# PIC32CX0525SG12144 register map
Vendor: Microchip Technology; Series: 0525SG12; File version: 0
CPU: CM4 r1p0, little endian, no MPU, no FPU, 3 interrupt priority bits, 172 interrupts
Registers are 32-bit, read-write, reset 0x0 unless marked. A register's access mark holds for its fields unless they carry their own. Offsets are from the block's base; [hi:lo] are bit positions; {n}, {i} and the like mark numbered series; 'fields as' and 'values as' point back to an identical list.

## DMA_MAIN — DMA Main Registers
Base 0x40002400
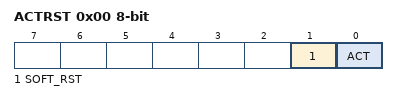
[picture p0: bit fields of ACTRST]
0x00 ACTRST 8-bit — Soft reset the entire module. Enable the blocks operation.
  [1] SOFT_RST — Soft reset the entire module. This bit is self-clearing.
  [0] ACT — Enable the blocks operation. (R/WS). 1=Enable block. Each individual channel must be enabled separately. 0=Disable all channels.
0x04 DATA_PKT ro — Debug register that has the data that is stored in the Data Packet. This data is read data from the currently active transfer source.

## ESPI_MSVW00_06 — The ESPI VW Channel permits the System to emulate a set of wires that interconnect the system Core Logic with the EC
Base 0x400F9C00
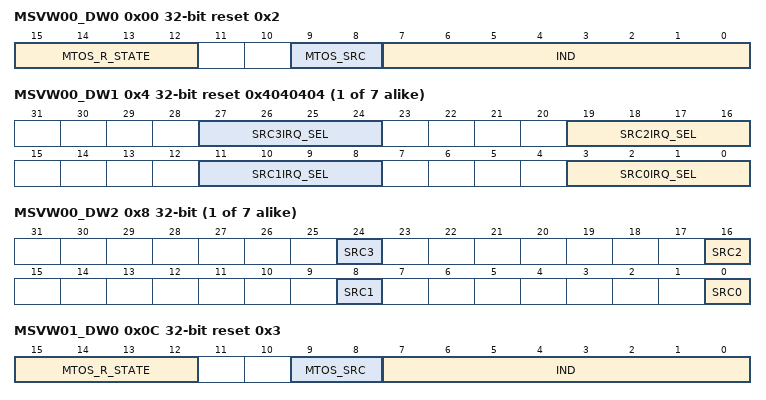
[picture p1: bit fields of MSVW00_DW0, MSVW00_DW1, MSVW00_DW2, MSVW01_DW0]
0x00 MSVW00_DW0 reset 0x2 — Master-to-Slave Virtual Wire 0 Register (DW 0)
  [15:12] MTOS_R_STATE — The four bits in this field are loaded into SRC0, SRC1, SRC2 and SRC3 when the reset signal selected by M2S RESET SRC is asserted. If MTOS_SRC is set for RESET_SYS, the SRC bits are set to the default value of this field, rather than its programmed value, since this field is also reset on RESET_SYS.
  [9:8] MTOS_SRC — This field determines which reset signal in addition to RESET_SYS resets SRC[3:0] in this register: 3=PLTRST. 2=RESET_SIO. 1=RESET_SYS. This is the only reset signal that will reset the SRC fields. 0=RESET_ESPI.
  [7:0] IND — The Index for SRC0, SRC1, SRC2 and SRC3. When the Index field of an incoming Master-to-Slave Virtual Wire transaction matches this value, the fields SRC0, SRC1, SRC2 and SRC3 are updated by the data contained in the respective bit positions in the transaction. Setting the INDEX field to 0 disables the register from accepting any Virtual Wire traffic from the Master. Setting the. INDEX field to 1 is illegal, since INDEX=1 is reserved for Serial IRQ.
{0x4+0xC*i} MSVW{i:02}_DW1 reset 0x4040404 (i=0..6) — Master-to-Slave Virtual Wire {i} Register (DW 1)
  [8n+3:8n] SRC{n}IRQ_SEL (n=0..3) — A change in the value of SRC{n} will generate an interrupt to the EC. Changes in the SRC register value caused by a Reset Event do not generate an interrupt.
{0x8+0xC*i} MSVW{i:02}_DW2 (i=0..6) — Master-to-Slave Virtual Wire {i} Register (DW 2)
  [8n] SRC{n} (n=0..3) — Master-to-Slave data for Bit Position {n} for the virtual wire associated with the index defined by INDEX.
0x0C MSVW01_DW0 reset 0x3 — Master-to-Slave Virtual Wire 1 Register (DW 0)
  fields as MSVW00_DW0
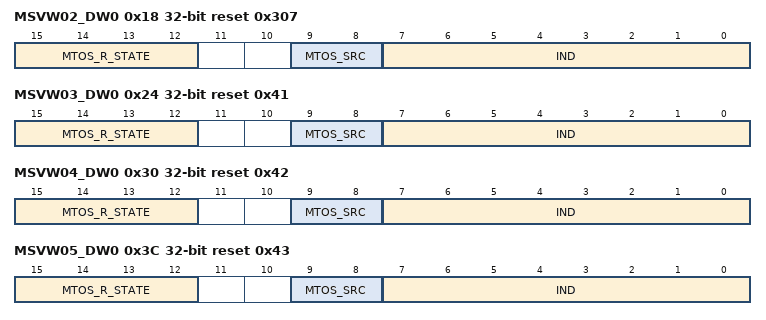
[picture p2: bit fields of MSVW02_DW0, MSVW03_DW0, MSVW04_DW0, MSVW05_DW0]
0x18 MSVW02_DW0 reset 0x307 — Master-to-Slave Virtual Wire 2 Register (DW 0)
  fields as MSVW00_DW0
0x24 MSVW03_DW0 reset 0x41 — Master-to-Slave Virtual Wire 3 Register (DW 0)
  fields as MSVW00_DW0
0x30 MSVW04_DW0 reset 0x42 — Master-to-Slave Virtual Wire 4 Register (DW 0)
  fields as MSVW00_DW0
0x3C MSVW05_DW0 reset 0x43 — Master-to-Slave Virtual Wire 5 Register (DW 0)
  fields as MSVW00_DW0
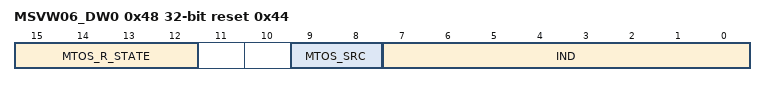
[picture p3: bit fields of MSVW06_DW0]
0x48 MSVW06_DW0 reset 0x44 — Master-to-Slave Virtual Wire 6 Register (DW 0)
  fields as MSVW00_DW0

## ESPI_MSVW07_10 — The ESPI VW Channel permits the System to emulate a set of wires that interconnect the system Core Logic with the EC
Base 0x400F9C54; register names take the prefix ESPI_MSVW07_1_
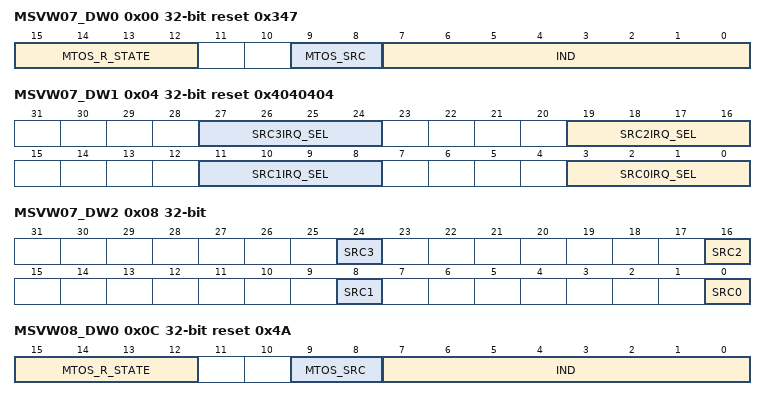
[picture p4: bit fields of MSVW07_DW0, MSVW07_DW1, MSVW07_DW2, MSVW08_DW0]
0x00 MSVW07_DW0 reset 0x347 — Master-to-Slave Virtual Wire 7 Register (DW 0)
  [15:12] MTOS_R_STATE — The four bits in this field are loaded into SRC0, SRC1, SRC2 and SRC3 when the reset signal selected by M2S RESET SRC is asserted. If MTOS_SRC is set for RESET_SYS, the SRC bits are set to the default value of this field, rather than its programmed value, since this field is also reset on RESET_SYS.
  [9:8] MTOS_SRC — This field determines which reset signal in addition to RESET_SYS resets SRC[3:0] in this register: 3=PLTRST. 2=RESET_SIO. 1=RESET_SYS. This is the only reset signal that will reset the SRC fields. 0=RESET_ESPI.
  [7:0] IND — The Index for SRC0, SRC1, SRC2 and SRC3. When the Index field of an incoming Master-to-Slave Virtual Wire transaction matches this value, the fields SRC0, SRC1, SRC2 and SRC3 are updated by the data contained in the respective bit positions in the transaction. Setting the INDEX field to 0 disables the register from accepting any Virtual Wire traffic from the Master. Setting the. INDEX field to 1 is illegal, since INDEX=1 is reserved for Serial IRQ.
0x04 MSVW07_DW1 reset 0x4040404 — Master-to-Slave Virtual Wire 7 Register (DW 1)
  [8n+3:8n] SRC{n}IRQ_SEL (n=0..3) — A change in the value of SRC{n} will generate an interrupt to the EC. Changes in the SRC register value caused by a Reset Event do not generate an interrupt.
0x08 MSVW07_DW2 — Master-to-Slave Virtual Wire 7 Register (DW 2)
  [8n] SRC{n} (n=0..3) — Master-to-Slave data for Bit Position {n} for the virtual wire associated with the index defined by INDEX.
0x0C MSVW08_DW0 reset 0x4A — Master-to-Slave Virtual Wire 8 Register (DW 0)
  fields as MSVW07_DW0
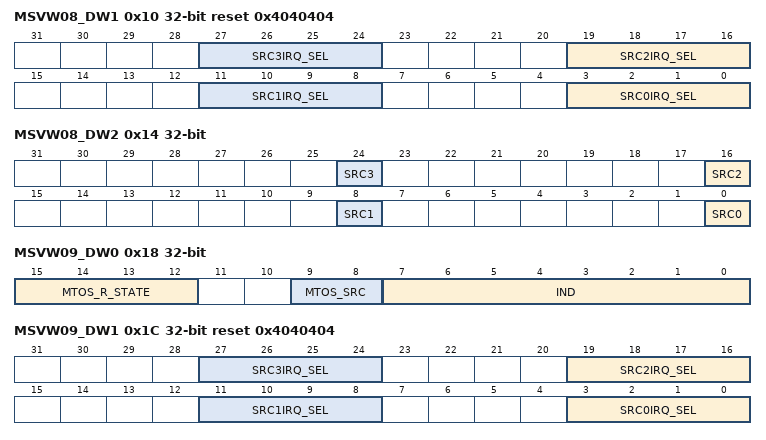
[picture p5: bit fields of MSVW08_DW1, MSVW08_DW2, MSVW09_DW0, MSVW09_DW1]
0x10 MSVW08_DW1 reset 0x4040404 — Master-to-Slave Virtual Wire 8 Register (DW 1)
  fields as MSVW07_DW1
0x14 MSVW08_DW2 — Master-to-Slave Virtual Wire 8 Register (DW 2)
  fields as MSVW07_DW2
0x18 MSVW09_DW0 — Master-to-Slave Virtual Wire 9 Register (DW 0)
  fields as MSVW07_DW0
0x1C MSVW09_DW1 reset 0x4040404 — Master-to-Slave Virtual Wire 9 Register (DW 1)
  fields as MSVW07_DW1
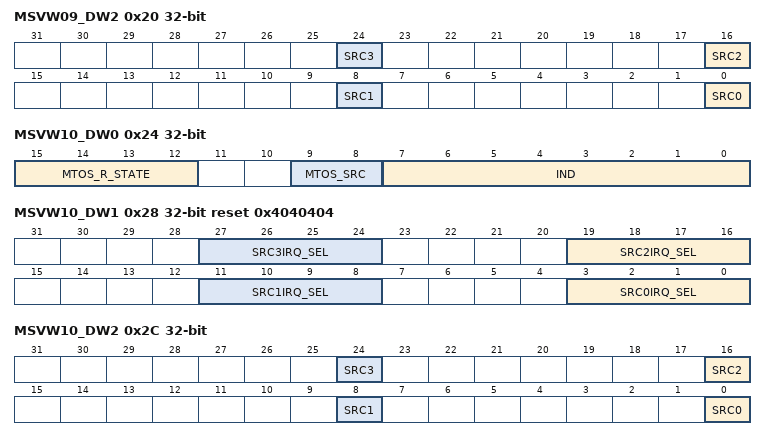
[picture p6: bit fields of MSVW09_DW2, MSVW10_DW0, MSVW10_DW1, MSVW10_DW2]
0x20 MSVW09_DW2 — Master-to-Slave Virtual Wire 9 Register (DW 2)
  fields as MSVW07_DW2
0x24 MSVW10_DW0 — Master-to-Slave Virtual Wire 10 Register (DW 0)
  fields as MSVW07_DW0
0x28 MSVW10_DW1 reset 0x4040404 — Master-to-Slave Virtual Wire 10 Register (DW 1)
  fields as MSVW07_DW1
0x2C MSVW10_DW2 — Master-to-Slave Virtual Wire 10 Register (DW 2)
  fields as MSVW07_DW2
